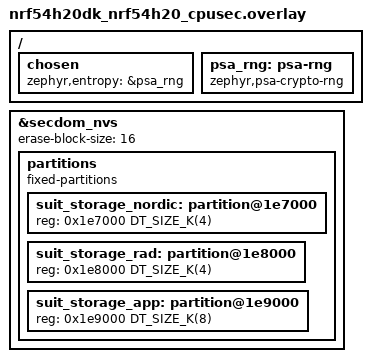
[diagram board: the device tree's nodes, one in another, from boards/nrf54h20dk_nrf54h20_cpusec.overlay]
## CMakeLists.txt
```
#
# Copyright (c) 2023 Nordic Semiconductor ASA
#
# SPDX-License-Identifier: LicenseRef-Nordic-5-Clause
#

cmake_minimum_required(VERSION 3.20.0)

find_package(Zephyr REQUIRED HINTS $ENV{ZEPHYR_BASE})

project(integration_test_suit_orchestrator)
include(../cmake/test_template.cmake)

# Link with the CMake target, that includes SUIT platform internal APIs header
zephyr_library_link_libraries(suit)
zephyr_library_link_libraries(suit_orchestrator_interface)
zephyr_library_link_libraries(suit_utils)
zephyr_library_link_libraries(suit_storage_interface)
zephyr_library_link_libraries(suit_update_magic_values)
zephyr_library_link_libraries(suit_cache_interface)
zephyr_library_link_libraries(suit_execution_mode)
```

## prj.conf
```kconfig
#
# Copyright (c) 2023 Nordic Semiconductor ASA
#
# SPDX-License-Identifier: LicenseRef-Nordic-5-Clause
#

CONFIG_ZTEST=y
CONFIG_ZTEST_NEW_API=y

CONFIG_SUIT=y
CONFIG_SUIT_CRYPTO=y
CONFIG_SUIT_MCI=y
CONFIG_SUIT_MCI_IMPL_CUSTOM=y
CONFIG_SUIT_METADATA=y
CONFIG_SUIT_ORCHESTRATOR=y
CONFIG_SUIT_PROCESSOR=y
CONFIG_SUIT_PLATFORM=y
CONFIG_SUIT_LOG_LEVEL_DBG=y

CONFIG_SUIT_UTILS=y
CONFIG_SUIT_CACHE=y
CONFIG_SUIT_STORAGE=y
CONFIG_SUIT_MEMPTR_STORAGE=y
CONFIG_SUIT_EXECUTION_MODE=y

CONFIG_ZCBOR=y
CONFIG_ZCBOR_CANONICAL=y

CONFIG_FLASH=y

CONFIG_SUIT_DEVCONFIG=y
CONFIG_SUIT_PLAT_CHECK_COMPONENT_COMPATIBILITY=y
CONFIG_SUIT_PLAT_CHECK_CLASSES=y
CONFIG_SUIT_AUTHENTICATE=y

CONFIG_SUIT_DIGEST=y
CONFIG_SUIT_DIGEST_CACHE=y
CONFIG_SUIT_SINK_SELECTOR=y

CONFIG_SUIT_STREAM=y
CONFIG_SUIT_STREAM_SINK_DIGEST=y
CONFIG_SUIT_CHECK_IMAGE_MATCH=y

CONFIG_SUIT_STREAM_SINK_MEMPTR=y
CONFIG_SUIT_STREAM_SINK_FLASH=y
CONFIG_FLASH_MAP=y
CONFIG_SUIT_STREAM_SOURCE_MEMPTR=y
CONFIG_SUIT_STREAM_SOURCE_CACHE=y
```

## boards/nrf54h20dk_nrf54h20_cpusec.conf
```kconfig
#
# Copyright (c) 2023 Nordic Semiconductor ASA
#
# SPDX-License-Identifier: LicenseRef-Nordic-5-Clause
#

CONFIG_NULL_POINTER_EXCEPTION_DETECTION_NONE=y
CONFIG_SERIAL=y
CONFIG_CONSOLE=y
CONFIG_UART_CONSOLE=y

# This test does not set 'IS_SECURE_DOMAIN_FW'. Hence, we need to enable the
# bare minimum configurations for running on bare metal Secure Domain.
CONFIG_SECDOM_UNIT_TEST_SUPPORT=y

# Logging and printk is using standard UART.
CONFIG_LOG_MODE_DEFERRED=y
CONFIG_LOG_BACKEND_UART=y
CONFIG_LOG_PRINTK=y
CONFIG_LOG_BUFFER_SIZE=8192
CONFIG_SOC_FLASH_NRF_MRAM_ONE_BYTE_WRITE_ACCESS=y

# Configure MPI, so it matches the test-specific MCI
CONFIG_SUIT_MPI_GENERATE=y
CONFIG_SUIT_MPI_ROOT_CLASS_NAME="test_sample_root"
CONFIG_SUIT_MPI_ROOT_INDEPENDENT_UPDATE=y
CONFIG_SUIT_MPI_ROOT_SIGNATURE_CHECK_ENABLED_ON_UPDATE_AND_BOOT=y
CONFIG_SUIT_MPI_APP_LOCAL_1=y
CONFIG_SUIT_MPI_APP_LOCAL_1_CLASS_NAME="test_sample_app"
CONFIG_SUIT_MPI_APP_LOCAL_1_INDEPENDENT_UPDATE=n
CONFIG_SUIT_MPI_APP_LOCAL_1_SIGNATURE_CHECK_ENABLED_ON_UPDATE_AND_BOOT=y
```

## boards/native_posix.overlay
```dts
/*
 * Copyright (c) 2023 Nordic Semiconductor ASA
 *
 * SPDX-License-Identifier: LicenseRef-Nordic-5-Clause
 */

&flash0 {
	partitions {
		compatible = "fixed-partitions";
		#address-cells = <1>;
		#size-cells = <1>;

		/* Use the last 32KB of NVM as suit storage. */
		suit_storage: partition@f8000 {
			label = "suit_storage";
			reg = <0xf8000 DT_SIZE_K(32)>;
		};
	};
};
```

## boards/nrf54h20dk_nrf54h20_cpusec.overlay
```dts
/*
 * Copyright (c) 2023 Nordic Semiconductor ASA
 *
 * SPDX-License-Identifier: LicenseRef-Nordic-5-Clause
 */

/ {
	chosen {
		zephyr,entropy = &psa_rng;
	};

	psa_rng: psa-rng {
		compatible = "zephyr,psa-crypto-rng";
		status = "okay";
	};
};

&secdom_nvs {
	erase-block-size = <16>;

	partitions {
		compatible = "fixed-partitions";
		#address-cells = <1>;
		#size-cells = <1>;

		/* Use the last 32 kB of SecDom SUIT NVM storage. */
		/* Use the first 4kB as area reserved for Secure domain. */
		suit_storage_nordic: partition@1e7000 {
			reg = <0x1e7000 DT_SIZE_K(4)>;
		};

		/* Use the next 4kB as area reserved for Radio domain. */
		suit_storage_rad: partition@1e8000 {
			reg = <0x1e8000 DT_SIZE_K(4)>;
		};

		/* Use the next 8kB as area reserved for Application domain. */
		suit_storage_app: partition@1e9000 {
			reg = <0x1e9000 DT_SIZE_K(8)>;
		};
	};
};
```

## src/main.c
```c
/*
 * Copyright (c) 2023 Nordic Semiconductor ASA
 *
 * SPDX-License-Identifier: LicenseRef-Nordic-5-Clause
 */

#include <zephyr/ztest.h>

#include <suit_orchestrator.h>

#include <suit_storage.h>
#include <suit_mci.h>
#include <suit_types.h>
#include <zephyr/drivers/flash.h>
#include <zephyr/storage/flash_map.h>
#include <suit_plat_mem_util.h>
#include <update_magic_values.h>
#include <dfu_cache.h>

#if DT_NODE_EXISTS(DT_NODELABEL(suit_storage_app))
#define SUIT_STORAGE_OFFSET FIXED_PARTITION_OFFSET(suit_storage_app)
#define SUIT_STORAGE_SIZE   FIXED_PARTITION_SIZE(suit_storage_app)
#else
#define SUIT_STORAGE_OFFSET FIXED_PARTITION_OFFSET(suit_storage)
#define SUIT_STORAGE_SIZE   FIXED_PARTITION_SIZE(suit_storage)
#endif
#define SUIT_STORAGE_ADDRESS suit_plat_mem_nvm_ptr_get(SUIT_STORAGE_OFFSET)

const suit_manifest_class_id_t supported_class_id = {{0x5b, 0x46, 0x9f, 0xd1, 0x90, 0xee, 0x53,
						      0x9c, 0xa3, 0x18, 0x68, 0x1b, 0x03, 0x69,
						      0x5e, 0x36}};

/* Valid envelope */
extern const uint8_t manifest_valid_buf[];
extern const size_t manifest_valid_len;

/* Manifest generated using component id with size field set to zero */
extern const uint8_t manifest_zero_size_buf[];
extern const size_t manifest_zero_size_len;

/* Originally valid envelope with manipulated single byte */
extern const uint8_t manifest_manipulated_buf[];
extern const size_t manifest_manipulated_len;

/* Envelope generated with "UNSUPPORTED!" as a component type */
extern const uint8_t manifest_unsupported_component_buf[];
extern const size_t manifest_unsupported_component_len;

/* Envelope with manifest version set to 2 */
extern const uint8_t manifest_wrong_version_buf[];
extern const size_t manifest_wrong_version_len;

/* Envelope signed with a different private key */
extern const uint8_t manifest_different_key_buf[];
extern const size_t manifest_different_key_len;

static void setup_erased_flash(void)
{
	/* Execute SUIT storage init, so the MPI area is copied into a backup region. */
	int err = suit_storage_init();
	zassert_equal(SUIT_PLAT_SUCCESS, err, "Failed to init and backup suit storage (%d)", err);

	/* Clear the whole application area */
	const struct device *fdev = DEVICE_DT_GET(DT_CHOSEN(zephyr_flash_controller));
	zassert_not_null(fdev, "Unable to find a driver to erase storage area");

	err = flash_erase(fdev, SUIT_STORAGE_OFFSET, SUIT_STORAGE_SIZE);
	zassert_equal(0, err, "Unable to erase storage before test execution");
}

static void setup_update_candidate(const uint8_t *buf, size_t len)
{
	zassert_not_null(buf, "NULL buf");

	suit_plat_mreg_t update_candidate[1] = {{
		.mem = buf,
		.size = len,
	}};

	setup_erased_flash();

	int err = suit_storage_init();
	zassert_equal(SUIT_PLAT_SUCCESS, err, "Failed to init suit storage (%d)", err);

	err = suit_storage_update_cand_set(update_candidate, ARRAY_SIZE(update_candidate));
	zassert_equal(SUIT_PLAT_SUCCESS, err,
		      "Unable to set update candidate before test execution (0x%x, %d)", buf, len);
}

ZTEST_SUITE(orchestrator_tests, NULL, NULL, NULL, NULL, NULL);

ZTEST(orchestrator_tests, test_boot_path_empty_storage)
{
	/* GIVEN empty flash (suit storage is erased)... */
	setup_erased_flash();
	/* ... and suit orchestrator is initialized */
	zassert_equal(0, suit_orchestrator_init(), "Orchestrator not initialized");

	/* WHEN orchestrator is launched */
	int err = suit_orchestrator_entry();

	/* THEN emergency recovery is triggered... */
	/* ... and orchestrator exits without an error */
	zassert_equal(0, err, "Unexpected error code");
}

ZTEST(orchestrator_tests, test_update_path_successful_update)
{
	uint8_t *addr;
	size_t size;

	/* GIVEN valid update candidate in suit storage... */
	setup_update_candidate(manifest_valid_buf, manifest_valid_len);
	/* ... and suit orchestrator is initialized */
	zassert_equal(0, suit_orchestrator_init(), "Orchestrator not initialized");

	/* WHEN orchestrator is launched */
	int err = suit_orchestrator_entry();

	/* THEN installation is performed successfully... */
	/* ... and orchestrator exits without an error */
	zassert_equal(0, err, "Unexpected error code");
	/* ... and the envelope get installed */
	err = suit_storage_installed_envelope_get(&supported_class_id, &addr, &size);
	zassert_equal(SUIT_PLAT_SUCCESS, err,
		      "The envelope was not installed after successful update");
}

ZTEST(orchestrator_tests, test_boot_path_successful_boot)
{
	uint8_t *addr_boot;
	size_t size_boot;
	uint8_t *addr_update;
	size_t size_update;

	/* GIVEN valid update candidate in suit storage... */
	setup_update_candidate(manifest_valid_buf, manifest_valid_len);
	/* ... and suit orchestrator is initialized... */
	zassert_equal(0, suit_orchestrator_init(), "Orchestrator not initialized first time");
	/* ... and orchestrator is launched first time to perform successful update */
	zassert_equal(0, suit_orchestrator_entry(), "Unsuccessful first orchestrator launch");
	/* ... and the bootable envelope is installed */
	int err = suit_storage_installed_envelope_get(&supported_class_id, &addr_boot, &size_boot);
	zassert_equal(SUIT_PLAT_SUCCESS, err,
		      "The envelope was not installed after successful update");

	/* WHEN when orchestrator is initialized again (reboot simulation)... */
	zassert_equal(0, suit_orchestrator_init(), "Orchestrator not initialized second time");
	/* ... and orchestrator is launched again */
	err = suit_orchestrator_entry();

	/* THEN installed SW is invoked successfully (orchestrator returns no error) */
	zassert_equal(0, err, "Unexpected error code");
	/* ... and the envelope remains installed */
	err = suit_storage_installed_envelope_get(&supported_class_id, &addr_update, &size_update);
	zassert_equal(SUIT_PLAT_SUCCESS, err,
		      "The envelope was not installed after successful update");
	/* .. and the same index in SUIT storage is used */
	zassert_equal(addr_boot, addr_update,
		      "The envelope was not installed in the same SUIT storage slot");
}

ZTEST(orchestrator_tests, test_update_path_size_zero)
{
	const suit_plat_mreg_t *regions = NULL;
	size_t len = 0;

	/* GIVEN suit storage contains envelope with component id's size field set to zero... */
	setup_update_candidate(manifest_zero_size_buf, manifest_zero_size_len);
	/* ... and orchestrator is initialized */
	zassert_equal(0, suit_orchestrator_init(), "Failed to setup test");

	/* WHEN orchestrator is launched */
	int err = suit_orchestrator_entry();

	/* THEN candidate availability flag is cleared... */
	suit_plat_err_t ret = suit_storage_update_cand_get(&regions, &len);
	zassert_equal(SUIT_PLAT_ERR_NOT_FOUND, ret, "Update candidate presence not cleared");

	/* ... and orchestrator returns success */
	zassert_equal(0, err, "Unexpected error code");
}

ZTEST(orchestrator_tests, test_update_path_manipulated_envelope)
{
	const suit_plat_mreg_t *regions = NULL;
	size_t len = 0;

	/* GIVEN suit storage contains envelope with one of its byte changed to different value...
	 */
	setup_update_candidate(manifest_manipulated_buf, manifest_manipulated_len);
	/* ... and suit orchestrator is initialized */
	zassert_equal(0, suit_orchestrator_init(), "Orchestrator not initialized");

	/* WHEN orchestrator is launched */
	int err = suit_orchestrator_entry();

	/* THEN candidate availability flag is cleared... */
	suit_plat_err_t ret = suit_storage_update_cand_get(&regions, &len);
	zassert_equal(SUIT_PLAT_ERR_NOT_FOUND, ret, "Update candidate presence not cleared");

	/* ... and orchestrator returns success */
	zassert_equal(0, err, "Unexpected error code");
}

ZTEST(orchestrator_tests, test_update_path_candidate_invalid_address_and_size)
{
	const suit_plat_mreg_t *regions = NULL;

	/* GIVEN suit storage indicates presence of update candidate... */
	/* ... but has empty address field...*/
	const uint8_t *buf = (const uint8_t *)UPDATE_MAGIC_VALUE_EMPTY;
	/* ... and has empty size field... */
	size_t len = (size_t)UPDATE_MAGIC_VALUE_EMPTY;
	setup_update_candidate(buf, len);

	/* ... and orchestrator is initialized */
	zassert_equal(0, suit_orchestrator_init(), "Orchestrator not initialized");

	/* WHEN orchestrator is launched */
	int err = suit_orchestrator_entry();

	/* THEN candidate availability flag is cleared... */
	suit_plat_err_t ret = suit_storage_update_cand_get(&regions, &len);
	zassert_equal(SUIT_PLAT_ERR_NOT_FOUND, ret, "Update candidate presence not cleared");

	/* ... and orchestrator returns success */
	zassert_equal(0, err, "Unexpected error code");
}

ZTEST(orchestrator_tests, test_update_path_candidate_empty_size)
{
	const suit_plat_mreg_t *regions = NULL;

	/* GIVEN suit storage has update candidate flag set... */
	/* ...and some non-empty and non-zero address field...*/
	const uint8_t *buf = (const uint8_t *)0xDEADBEEF;
	/* ... but empty size field... */
	size_t len = (size_t)UPDATE_MAGIC_VALUE_EMPTY;
	setup_update_candidate(buf, len);

	/* ... and orchestrator is initialized */
	zassert_equal(0, suit_orchestrator_init(), "Orchestrator not initialized");

	/* WHEN orchestrator is launched */
	int err = suit_orchestrator_entry();

	/* THEN candidate availability flag is cleared... */
	suit_plat_err_t ret = suit_storage_update_cand_get(&regions, &len);
	zassert_equal(SUIT_PLAT_ERR_NOT_FOUND, ret, "Update candidate presence not cleared");

	/* ... and orchestrator returns success */
	zassert_equal(0, err, "Unexpected error code");
}

ZTEST(orchestrator_tests, test_update_path_unsupported_component)
{
	const suit_plat_mreg_t *regions = NULL;
	size_t len = 0;

	/* GIVEN suit storage contains update candidate with unsupported component... */
	setup_update_candidate(manifest_unsupported_component_buf,
			       manifest_unsupported_component_len);
	/* ... and orchestrator is initialized */
	zassert_equal(0, suit_orchestrator_init(), "Orchestrator not initialized");

	/* WHEN orchestrator is launched */
	int err = suit_orchestrator_entry();

	/* THEN candidate availability flag is cleared... */
	suit_plat_err_t ret = suit_storage_update_cand_get(&regions, &len);
	zassert_equal(SUIT_PLAT_ERR_NOT_FOUND, ret, "Update candidate presence not cleared");

	/* ... and orchestrator returns success */
	zassert_equal(0, err, "Unexpected error code");
}

ZTEST(orchestrator_tests, test_update_path_wrong_manifest_version)
{
	const suit_plat_mreg_t *regions = NULL;
	size_t len = 0;

	/* GIVEN suit storage contains update candidate with invalid manifest version... */
	setup_update_candidate(manifest_wrong_version_buf, manifest_wrong_version_len);

	/* ... and orchestrator is initialized */
	zassert_equal(0, suit_orchestrator_init(), "Orchestrator not initialized");

	/* WHEN orchestrator is launched */
	int err = suit_orchestrator_entry();

	/* THEN candidate availability flag is cleared... */
	suit_plat_err_t ret = suit_storage_update_cand_get(&regions, &len);
	zassert_equal(SUIT_PLAT_ERR_NOT_FOUND, ret, "Update candidate presence not cleared");

	/* ... and orchestrator returns success */
	zassert_equal(0, err, "Unexpected error code");
}

ZTEST(orchestrator_tests, test_update_path_signed_with_different_key)
{
	const suit_plat_mreg_t *regions = NULL;
	size_t len = 0;

	/* GIVEN suit storage contains update candidate with invalid manifest version... */
	setup_update_candidate(manifest_different_key_buf, manifest_different_key_len);

	/* ... and orchestrator is initialized */
	zassert_equal(0, suit_orchestrator_init(), "Orchestrator not initialized");

	/* WHEN orchestrator is launched */
	int err = suit_orchestrator_entry();

	/* THEN candidate availability flag is cleared... */
	suit_plat_err_t ret = suit_storage_update_cand_get(&regions, &len);
	zassert_equal(SUIT_PLAT_ERR_NOT_FOUND, ret, "Update candidate presence not cleared");

	/* ... and orchestrator returns success */
	zassert_equal(0, err, "Unexpected error code");
}
```

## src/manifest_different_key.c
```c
/*
 * Copyright (c) 2023 Nordic Semiconductor ASA
 *
 * SPDX-License-Identifier: LicenseRef-Nordic-5-Clause
 */

#if defined(CONFIG_SOC_NRF52840) || defined(CONFIG_BOARD_NATIVE_POSIX)
#include <stdint.h>
#include <stddef.h>

/** @brief Valid SUIT envelope but signed using different private key
 *
 * @details New, temporary private key was created and used for signing.
 *          Signature won't pass verification with a private key used in our tests.
 */
const uint8_t manifest_different_key_buf[] = {
	0xD8, 0x6B, 0xA4, 0x02, 0x58, 0x7A, 0x82, 0x58, 0x24, 0x82, 0x2F, 0x58, 0x20, 0xA9, 0xF6,
	0x31, 0xAA, 0x0A, 0x36, 0x9D, 0x8A, 0xE8, 0xF2, 0x8F, 0xF2, 0x83, 0x4C, 0x2E, 0x54, 0x65,
	0x37, 0x57, 0xD3, 0x90, 0xDE, 0x10, 0xA4, 0x7C, 0x70, 0xE8, 0x5D, 0x9C, 0xF2, 0xDC, 0x9F,
	0x58, 0x51, 0xD2, 0x84, 0x4A, 0xA2, 0x01, 0x26, 0x04, 0x45, 0x1A, 0x7F, 0xFF, 0xFF, 0xE0,
	0xA0, 0xF6, 0x58, 0x40, 0x22, 0xFD, 0x9A, 0x52, 0x84, 0xE2, 0x15, 0x10, 0x0B, 0xE5, 0x1A,
	0x68, 0x41, 0x1E, 0x7E, 0x18, 0x03, 0x76, 0x58, 0x19, 0xD0, 0xD5, 0x9C, 0xC2, 0xEA, 0x98,
	0x86, 0x63, 0x51, 0x12, 0x82, 0x10, 0x66, 0xC9, 0xFE, 0x28, 0xE1, 0x12, 0xE0, 0xB2, 0x56,
	0xB7, 0xDA, 0xB0, 0x8E, 0xB9, 0x34, 0xCE, 0xA9, 0x5D, 0x27, 0x26, 0xCD, 0xEA, 0x4D, 0x04,
	0x5F, 0x61, 0xF0, 0xC1, 0xD1, 0x9C, 0xBA, 0x2B, 0x03, 0x58, 0xD9, 0xA8, 0x01, 0x01, 0x02,
	0x01, 0x03, 0x58, 0x6E, 0xA2, 0x02, 0x81, 0x84, 0x44, 0x63, 0x4D, 0x45, 0x4D, 0x41, 0x00,
	0x45, 0x1A, 0x00, 0x08, 0x00, 0x00, 0x43, 0x19, 0x10, 0x00, 0x04, 0x58, 0x56, 0x86, 0x14,
	0xA4, 0x01, 0x50, 0x76, 0x17, 0xDA, 0xA5, 0x71, 0xFD, 0x5A, 0x85, 0x8F, 0x94, 0xE2, 0x8D,
	0x73, 0x5C, 0xE9, 0xF4, 0x02, 0x50, 0x5B, 0x46, 0x9F, 0xD1, 0x90, 0xEE, 0x53, 0x9C, 0xA3,
	0x18, 0x68, 0x1B, 0x03, 0x69, 0x5E, 0x36, 0x03, 0x58, 0x24, 0x82, 0x2F, 0x58, 0x20, 0x5F,
	0xC3, 0x54, 0xBF, 0x8E, 0x8C, 0x50, 0xFB, 0x4F, 0xBC, 0x2C, 0xFA, 0xEB, 0x04, 0x53, 0x41,
	0xC9, 0x80, 0x6D, 0xEA, 0xBD, 0xCB, 0x41, 0x54, 0xFB, 0x79, 0xCC, 0xA4, 0xF0, 0xC9, 0x8C,
	0x12, 0x0E, 0x19, 0x01, 0x00, 0x01, 0x0F, 0x02, 0x0F, 0x07, 0x43, 0x82, 0x03, 0x0F, 0x09,
	0x43, 0x82, 0x17, 0x02, 0x11, 0x52, 0x86, 0x14, 0xA1, 0x15, 0x69, 0x23, 0x66, 0x69, 0x6C,
	0x65, 0x2E, 0x62, 0x69, 0x6E, 0x15, 0x02, 0x03, 0x0F, 0x17, 0x82, 0x2F, 0x58, 0x20, 0x8C,
	0x70, 0x17, 0x9B, 0x73, 0x6B, 0x68, 0x9F, 0x02, 0x7D, 0x2D, 0xF6, 0x78, 0x00, 0xB0, 0xA4,
	0x38, 0x52, 0x8F, 0x9C, 0x67, 0xA1, 0x37, 0xF4, 0xB0, 0xCA, 0x78, 0xCB, 0x36, 0x96, 0x16,
	0x4F, 0x05, 0x82, 0x4C, 0x6B, 0x49, 0x4E, 0x53, 0x54, 0x4C, 0x44, 0x5F, 0x4D, 0x46, 0x53,
	0x54, 0x50, 0x5B, 0x46, 0x9F, 0xD1, 0x90, 0xEE, 0x53, 0x9C, 0xA3, 0x18, 0x68, 0x1B, 0x03,
	0x69, 0x5E, 0x36, 0x17, 0x58, 0x82, 0xA1, 0x84, 0x44, 0x63, 0x4D, 0x45, 0x4D, 0x41, 0x00,
	0x45, 0x1A, 0x00, 0x08, 0x00, 0x00, 0x43, 0x19, 0x10, 0x00, 0xA6, 0x01, 0x78, 0x18, 0x4E,
	0x6F, 0x72, 0x64, 0x69, 0x63, 0x20, 0x53, 0x65, 0x6D, 0x69, 0x63, 0x6F, 0x6E, 0x64, 0x75,
	0x63, 0x74, 0x6F, 0x72, 0x20, 0x41, 0x53, 0x41, 0x02, 0x64, 0x74, 0x65, 0x73, 0x74, 0x03,
	0x6E, 0x6E, 0x6F, 0x72, 0x64, 0x69, 0x63, 0x73, 0x65, 0x6D, 0x69, 0x2E, 0x63, 0x6F, 0x6D,
	0x04, 0x74, 0x54, 0x68, 0x65, 0x20, 0x74, 0x65, 0x73, 0x74, 0x20, 0x61, 0x70, 0x70, 0x6C,
	0x69, 0x63, 0x61, 0x74, 0x69, 0x6F, 0x6E, 0x05, 0x78, 0x1C, 0x53, 0x61, 0x6D, 0x70, 0x6C,
	0x65, 0x20, 0x61, 0x70, 0x70, 0x6C, 0x69, 0x63, 0x61, 0x74, 0x69, 0x6F, 0x6E, 0x20, 0x66,
	0x6F, 0x72, 0x20, 0x74, 0x65, 0x73, 0x74, 0x73, 0x06, 0x66, 0x76, 0x31, 0x2E, 0x30, 0x2E,
	0x30, 0x69, 0x23, 0x66, 0x69, 0x6C, 0x65, 0x2E, 0x62, 0x69, 0x6E, 0x59, 0x01, 0x00, 0xC7,
	0x9C, 0xAB, 0x9D, 0xE8, 0x33, 0x7F, 0x30, 0x14, 0xEB, 0xAC, 0x02, 0xAF, 0x26, 0x01, 0x5E,
	0x80, 0x6D, 0x88, 0xA1, 0xDB, 0x11, 0xA7, 0x31, 0xDF, 0xA6, 0xEC, 0xCB, 0x9B, 0x48, 0x0D,
	0xC8, 0x34, 0x40, 0x6D, 0x30, 0x86, 0x7D, 0xE8, 0x1B, 0xEC, 0x3C, 0xF5, 0x40, 0xD0, 0x48,
	0x18, 0x82, 0x11, 0x9D, 0x7C, 0x3F, 0x6C, 0xE5, 0x8F, 0xF1, 0xD3, 0x5D, 0xE1, 0x51, 0xF7,
	0x6A, 0x0F, 0xAF, 0x0B, 0xBD, 0x4C, 0x5F, 0xA5, 0x34, 0x1A, 0x66, 0xDB, 0x22, 0xEC, 0x63,
	0xED, 0x4B, 0xAB, 0xC7, 0xC8, 0xF7, 0x59, 0xD8, 0xD6, 0x9E, 0xEC, 0x71, 0x1B, 0x24, 0x20,
	0xB9, 0xAE, 0xE1, 0x3B, 0xFC, 0xAE, 0xB8, 0x77, 0xAC, 0xA4, 0x57, 0x34, 0x97, 0x84, 0x4F,
	0x58, 0xD5, 0x68, 0x08, 0x6F, 0xE3, 0x9C, 0x7E, 0x1B, 0xD7, 0x38, 0x22, 0x98, 0x48, 0xF8,
	0x7A, 0x67, 0xB2, 0xD9, 0xAC, 0xC5, 0x34, 0xC1, 0x27, 0x82, 0x8E, 0x42, 0x79, 0x84, 0x21,
	0x37, 0x4C, 0x41, 0x4A, 0x0F, 0xE2, 0x7F, 0xA0, 0x6A, 0x19, 0x13, 0x3D, 0x52, 0x22, 0x7F,
	0xD6, 0x2F, 0x71, 0x12, 0x76, 0xAB, 0x25, 0x9C, 0xFC, 0x67, 0x08, 0x03, 0x7C, 0xDB, 0x18,
	0xE6, 0x45, 0xF8, 0x99, 0xC2, 0x9E, 0x2C, 0xE3, 0x9B, 0x25, 0xA9, 0x7B, 0x09, 0xFF, 0x00,
	0x57, 0x26, 0x08, 0x0A, 0x11, 0x42, 0xCF, 0x82, 0xA2, 0x6B, 0x2A, 0x99, 0xF9, 0x71, 0x9D,
	0x14, 0x19, 0x5C, 0x5C, 0x78, 0x31, 0x60, 0x42, 0x4A, 0x18, 0x1F, 0xEC, 0x78, 0x6A, 0x9A,
	0x7C, 0x4F, 0xCF, 0xE8, 0x5A, 0x29, 0x65, 0xCD, 0x01, 0x3B, 0x6D, 0x53, 0xBB, 0xC6, 0xDB,
	0xDA, 0xD5, 0x8F, 0xF7, 0xF4, 0xD9, 0xB9, 0x0A, 0x03, 0x4B, 0xFF, 0x33, 0xAB, 0x3B, 0xC5,
	0xAF, 0xD0, 0xB8, 0x2C, 0x0F, 0x6A, 0xA9, 0x11, 0xB0, 0xE8, 0x57, 0x8C, 0x92, 0x53, 0x81};

const size_t manifest_different_key_len = sizeof(manifest_different_key_buf);

#endif /* CONFIG_SOC_NRF52840 || CONFIG_BOARD_NATIVE_POSIX */
```

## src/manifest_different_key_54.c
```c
/*
 * Copyright (c) 2023 Nordic Semiconductor ASA
 *
 * SPDX-License-Identifier: LicenseRef-Nordic-5-Clause
 */

#if defined(CONFIG_SOC_NRF54H20)
#include <stdint.h>
#include <stddef.h>

/** @brief Valid SUIT envelope but signed using different private key
 *
 * @details New, temporary private key was created and used for signing.
 *          Signature won't pass verification with a private key used in our tests.
 */
const uint8_t manifest_different_key_buf[] = {
	0xD8, 0x6B, 0xA4, 0x02, 0x58, 0x7A, 0x82, 0x58, 0x24, 0x82, 0x2F, 0x58, 0x20, 0x67, 0xBE,
	0x1B, 0x3A, 0x2B, 0x20, 0xCC, 0x03, 0x4F, 0xB5, 0xAA, 0x49, 0x82, 0xDF, 0x34, 0x2F, 0x4F,
	0xDD, 0x80, 0x60, 0x71, 0x17, 0x13, 0x87, 0xED, 0x06, 0xA0, 0x4F, 0xD3, 0x31, 0xC3, 0x61,
	0x58, 0x51, 0xD2, 0x84, 0x4A, 0xA2, 0x01, 0x26, 0x04, 0x45, 0x1A, 0x7F, 0xFF, 0xFF, 0xE0,
	0xA0, 0xF6, 0x58, 0x40, 0x67, 0x03, 0xC6, 0x26, 0x2B, 0xB7, 0x29, 0x56, 0xFA, 0x31, 0xF8,
	0x28, 0x14, 0xAB, 0xCB, 0x11, 0x61, 0x9B, 0xF6, 0xC4, 0x54, 0xE6, 0x29, 0xF4, 0x4B, 0xB6,
	0xCD, 0xEE, 0xE2, 0x92, 0xE7, 0xBC, 0x35, 0xE2, 0x23, 0x1A, 0x5F, 0x25, 0x46, 0xD0, 0x21,
	0x4B, 0xFC, 0xB0, 0xA9, 0xE3, 0xBC, 0xD5, 0xA1, 0x1C, 0x18, 0x72, 0xC2, 0xA7, 0x1F, 0x79,
	0x1B, 0x6C, 0x00, 0xBF, 0x84, 0x5F, 0x03, 0xAA, 0x03, 0x58, 0xD9, 0xA8, 0x01, 0x01, 0x02,
	0x01, 0x03, 0x58, 0x6E, 0xA2, 0x02, 0x81, 0x84, 0x44, 0x63, 0x4D, 0x45, 0x4D, 0x41, 0x00,
	0x45, 0x1A, 0x0E, 0x0A, 0xA0, 0x00, 0x43, 0x19, 0x10, 0x00, 0x04, 0x58, 0x56, 0x86, 0x14,
	0xA4, 0x01, 0x50, 0x76, 0x17, 0xDA, 0xA5, 0x71, 0xFD, 0x5A, 0x85, 0x8F, 0x94, 0xE2, 0x8D,
	0x73, 0x5C, 0xE9, 0xF4, 0x02, 0x50, 0x5B, 0x46, 0x9F, 0xD1, 0x90, 0xEE, 0x53, 0x9C, 0xA3,
	0x18, 0x68, 0x1B, 0x03, 0x69, 0x5E, 0x36, 0x03, 0x58, 0x24, 0x82, 0x2F, 0x58, 0x20, 0x5F,
	0xC3, 0x54, 0xBF, 0x8E, 0x8C, 0x50, 0xFB, 0x4F, 0xBC, 0x2C, 0xFA, 0xEB, 0x04, 0x53, 0x41,
	0xC9, 0x80, 0x6D, 0xEA, 0xBD, 0xCB, 0x41, 0x54, 0xFB, 0x79, 0xCC, 0xA4, 0xF0, 0xC9, 0x8C,
	0x12, 0x0E, 0x19, 0x01, 0x00, 0x01, 0x0F, 0x02, 0x0F, 0x07, 0x43, 0x82, 0x03, 0x0F, 0x09,
	0x43, 0x82, 0x17, 0x02, 0x11, 0x52, 0x86, 0x14, 0xA1, 0x15, 0x69, 0x23, 0x66, 0x69, 0x6C,
	0x65, 0x2E, 0x62, 0x69, 0x6E, 0x15, 0x02, 0x03, 0x0F, 0x17, 0x82, 0x2F, 0x58, 0x20, 0x69,
	0x74, 0xD1, 0x61, 0x69, 0x08, 0x2F, 0x10, 0xAE, 0x48, 0x6C, 0x5B, 0x12, 0x82, 0x40, 0x9C,
	0xFD, 0x63, 0xCC, 0xC8, 0x35, 0x4D, 0xBE, 0x55, 0x15, 0xCC, 0xE6, 0xCE, 0x8F, 0x37, 0xDE,
	0x71, 0x05, 0x82, 0x4C, 0x6B, 0x49, 0x4E, 0x53, 0x54, 0x4C, 0x44, 0x5F, 0x4D, 0x46, 0x53,
	0x54, 0x50, 0x5B, 0x46, 0x9F, 0xD1, 0x90, 0xEE, 0x53, 0x9C, 0xA3, 0x18, 0x68, 0x1B, 0x03,
	0x69, 0x5E, 0x36, 0x17, 0x58, 0x82, 0xA1, 0x84, 0x44, 0x63, 0x4D, 0x45, 0x4D, 0x41, 0x00,
	0x45, 0x1A, 0x0E, 0x0A, 0xA0, 0x00, 0x43, 0x19, 0x10, 0x00, 0xA6, 0x01, 0x78, 0x18, 0x4E,
	0x6F, 0x72, 0x64, 0x69, 0x63, 0x20, 0x53, 0x65, 0x6D, 0x69, 0x63, 0x6F, 0x6E, 0x64, 0x75,
	0x63, 0x74, 0x6F, 0x72, 0x20, 0x41, 0x53, 0x41, 0x02, 0x64, 0x74, 0x65, 0x73, 0x74, 0x03,
	0x6E, 0x6E, 0x6F, 0x72, 0x64, 0x69, 0x63, 0x73, 0x65, 0x6D, 0x69, 0x2E, 0x63, 0x6F, 0x6D,
	0x04, 0x74, 0x54, 0x68, 0x65, 0x20, 0x74, 0x65, 0x73, 0x74, 0x20, 0x61, 0x70, 0x70, 0x6C,
	0x69, 0x63, 0x61, 0x74, 0x69, 0x6F, 0x6E, 0x05, 0x78, 0x1C, 0x53, 0x61, 0x6D, 0x70, 0x6C,
	0x65, 0x20, 0x61, 0x70, 0x70, 0x6C, 0x69, 0x63, 0x61, 0x74, 0x69, 0x6F, 0x6E, 0x20, 0x66,
	0x6F, 0x72, 0x20, 0x74, 0x65, 0x73, 0x74, 0x73, 0x06, 0x66, 0x76, 0x31, 0x2E, 0x30, 0x2E,
	0x30, 0x69, 0x23, 0x66, 0x69, 0x6C, 0x65, 0x2E, 0x62, 0x69, 0x6E, 0x59, 0x01, 0x00, 0xC7,
	0x9C, 0xAB, 0x9D, 0xE8, 0x33, 0x7F, 0x30, 0x14, 0xEB, 0xAC, 0x02, 0xAF, 0x26, 0x01, 0x5E,
	0x80, 0x6D, 0x88, 0xA1, 0xDB, 0x11, 0xA7, 0x31, 0xDF, 0xA6, 0xEC, 0xCB, 0x9B, 0x48, 0x0D,
	0xC8, 0x34, 0x40, 0x6D, 0x30, 0x86, 0x7D, 0xE8, 0x1B, 0xEC, 0x3C, 0xF5, 0x40, 0xD0, 0x48,
	0x18, 0x82, 0x11, 0x9D, 0x7C, 0x3F, 0x6C, 0xE5, 0x8F, 0xF1, 0xD3, 0x5D, 0xE1, 0x51, 0xF7,
	0x6A, 0x0F, 0xAF, 0x0B, 0xBD, 0x4C, 0x5F, 0xA5, 0x34, 0x1A, 0x66, 0xDB, 0x22, 0xEC, 0x63,
	0xED, 0x4B, 0xAB, 0xC7, 0xC8, 0xF7, 0x59, 0xD8, 0xD6, 0x9E, 0xEC, 0x71, 0x1B, 0x24, 0x20,
	0xB9, 0xAE, 0xE1, 0x3B, 0xFC, 0xAE, 0xB8, 0x77, 0xAC, 0xA4, 0x57, 0x34, 0x97, 0x84, 0x4F,
	0x58, 0xD5, 0x68, 0x08, 0x6F, 0xE3, 0x9C, 0x7E, 0x1B, 0xD7, 0x38, 0x22, 0x98, 0x48, 0xF8,
	0x7A, 0x67, 0xB2, 0xD9, 0xAC, 0xC5, 0x34, 0xC1, 0x27, 0x82, 0x8E, 0x42, 0x79, 0x84, 0x21,
	0x37, 0x4C, 0x41, 0x4A, 0x0F, 0xE2, 0x7F, 0xA0, 0x6A, 0x19, 0x13, 0x3D, 0x52, 0x22, 0x7F,
	0xD6, 0x2F, 0x71, 0x12, 0x76, 0xAB, 0x25, 0x9C, 0xFC, 0x67, 0x08, 0x03, 0x7C, 0xDB, 0x18,
	0xE6, 0x45, 0xF8, 0x99, 0xC2, 0x9E, 0x2C, 0xE3, 0x9B, 0x25, 0xA9, 0x7B, 0x09, 0xFF, 0x00,
	0x57, 0x26, 0x08, 0x0A, 0x11, 0x42, 0xCF, 0x82, 0xA2, 0x6B, 0x2A, 0x99, 0xF9, 0x71, 0x9D,
	0x14, 0x19, 0x5C, 0x5C, 0x78, 0x31, 0x60, 0x42, 0x4A, 0x18, 0x1F, 0xEC, 0x78, 0x6A, 0x9A,
	0x7C, 0x4F, 0xCF, 0xE8, 0x5A, 0x29, 0x65, 0xCD, 0x01, 0x3B, 0x6D, 0x53, 0xBB, 0xC6, 0xDB,
	0xDA, 0xD5, 0x8F, 0xF7, 0xF4, 0xD9, 0xB9, 0x0A, 0x03, 0x4B, 0xFF, 0x33, 0xAB, 0x3B, 0xC5,
	0xAF, 0xD0, 0xB8, 0x2C, 0x0F, 0x6A, 0xA9, 0x11, 0xB0, 0xE8, 0x57, 0x8C, 0x92, 0x53, 0x81};

const size_t manifest_different_key_len = sizeof(manifest_different_key_buf);

#endif /* CONFIG_SOC_NRF54H20 */
```

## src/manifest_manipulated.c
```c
/*
 * Copyright (c) 2023 Nordic Semiconductor ASA
 *
 * SPDX-License-Identifier: LicenseRef-Nordic-5-Clause
 */

#if defined(CONFIG_SOC_NRF52840) || defined(CONFIG_BOARD_NATIVE_POSIX)
#include <stdint.h>
#include <stddef.h>

/** @brief Manipulated SUIT envelope, based on ../manifest/sample_valid.yaml
 *
 * @details The manipulation is done on byte of index 7, from value 0x58 to 0xFF
 *
 */
const uint8_t manifest_manipulated_buf[] = {
	0xD8, 0x6B, 0xA4, 0x02, 0x58, 0x7A, 0x82, 0x58, 0x24, 0x82, 0x2F, 0xFF, 0x20, 0x99, 0x0B,
	0xD3, 0xF5, 0x19, 0xBD, 0x5A, 0x13, 0xA3, 0x46, 0x7D, 0x99, 0x75, 0xA6, 0x46, 0x0D, 0x0B,
	0xD7, 0xA5, 0xFE, 0xA4, 0x15, 0x99, 0x27, 0xBC, 0xB1, 0xD5, 0x9B, 0x31, 0x2D, 0x7D, 0xAE,
	0x58, 0x51, 0xD2, 0x84, 0x4A, 0xA2, 0x01, 0x26, 0x04, 0x45, 0x1A, 0x7F, 0xFF, 0xFF, 0xE0,
	0xA0, 0xF6, 0x58, 0x40, 0xFC, 0x79, 0x84, 0xAB, 0x2C, 0xF2, 0x2D, 0xBC, 0x13, 0xF5, 0x2D,
	0x12, 0x6A, 0xE5, 0xDC, 0xC8, 0x84, 0xB0, 0xFF, 0x09, 0xE1, 0x60, 0x0A, 0xBD, 0x86, 0x9F,
	0xED, 0xA4, 0xEB, 0x52, 0x7D, 0x51, 0xC4, 0x31, 0xAB, 0x21, 0x8A, 0x40, 0x58, 0xDC, 0xF3,
	0x6B, 0x1E, 0x2B, 0x83, 0x87, 0x88, 0x96, 0xBD, 0x0D, 0xAB, 0x85, 0x5D, 0x6D, 0xD3, 0x9A,
	0x8B, 0xE1, 0x05, 0xB0, 0xE5, 0x12, 0x5D, 0x2F, 0x03, 0x59, 0x01, 0x07, 0xA8, 0x01, 0x01,
	0x02, 0x01, 0x03, 0x58, 0x66, 0xA3, 0x02, 0x82, 0x82, 0x4A, 0x69, 0x43, 0x41, 0x4E, 0x44,
	0x5F, 0x4D, 0x46, 0x53, 0x54, 0x41, 0x00, 0x82, 0x4C, 0x6B, 0x49, 0x4E, 0x53, 0x54, 0x4C,
	0x44, 0x5F, 0x4D, 0x46, 0x53, 0x54, 0x50, 0x5B, 0x46, 0x9F, 0xD1, 0x90, 0xEE, 0x53, 0x9C,
	0xA3, 0x18, 0x68, 0x1B, 0x03, 0x69, 0x5E, 0x36, 0x04, 0x58, 0x2D, 0x88, 0x0C, 0x01, 0x14,
	0xA2, 0x01, 0x50, 0x76, 0x17, 0xDA, 0xA5, 0x71, 0xFD, 0x5A, 0x85, 0x8F, 0x94, 0xE2, 0x8D,
	0x73, 0x5C, 0xE9, 0xF4, 0x02, 0x50, 0x5B, 0x46, 0x9F, 0xD1, 0x90, 0xEE, 0x53, 0x9C, 0xA3,
	0x18, 0x68, 0x1B, 0x03, 0x69, 0x5E, 0x36, 0x01, 0x0F, 0x02, 0x0F, 0x01, 0xA2, 0x00, 0xA0,
	0x01, 0xA0, 0x07, 0x47, 0x86, 0x0C, 0x01, 0x07, 0x0F, 0x0B, 0x0F, 0x09, 0x47, 0x86, 0x0C,
	0x01, 0x07, 0x0F, 0x0B, 0x0F, 0x11, 0x58, 0x3F, 0x8C, 0x0C, 0x00, 0x14, 0xA2, 0x15, 0x69,
	0x23, 0x61, 0x70, 0x70, 0x2E, 0x73, 0x75, 0x69, 0x74, 0x03, 0x58, 0x24, 0x82, 0x2F, 0x58,
	0x20, 0xA9, 0xF6, 0x31, 0xAA, 0x0A, 0x36, 0x9D, 0x8A, 0xE8, 0xF2, 0x8F, 0xF2, 0x83, 0x4C,
	0x2E, 0x54, 0x65, 0x37, 0x57, 0xD3, 0x90, 0xDE, 0x10, 0xA4, 0x7C, 0x70, 0xE8, 0x5D, 0x9C,
	0xF2, 0xDC, 0x9F, 0x15, 0x02, 0x03, 0x0F, 0x07, 0x0F, 0x0B, 0x0F, 0x17, 0x82, 0x2F, 0x58,
	0x20, 0x4C, 0x3E, 0x23, 0xA0, 0xD3, 0x56, 0xE9, 0xA6, 0xF7, 0xDA, 0xD8, 0x0C, 0xAB, 0x79,
	0x53, 0x8F, 0x88, 0xCD, 0x18, 0xC7, 0x17, 0x35, 0xDE, 0xCB, 0x4A, 0xF5, 0x3C, 0xC2, 0xE8,
	0xD6, 0x26, 0xC9, 0x05, 0x82, 0x4C, 0x6B, 0x49, 0x4E, 0x53, 0x54, 0x4C, 0x44, 0x5F, 0x4D,
	0x46, 0x53, 0x54, 0x50, 0x97, 0x05, 0x48, 0x23, 0x4C, 0x3D, 0x59, 0xA1, 0x89, 0x86, 0xA5,
	0x46, 0x60, 0xA1, 0x4B, 0x0A, 0x17, 0x58, 0x77, 0xA1, 0x82, 0x4A, 0x69, 0x43, 0x41, 0x4E,
	0x44, 0x5F, 0x4D, 0x46, 0x53, 0x54, 0x41, 0x00, 0xA6, 0x01, 0x78, 0x18, 0x4E, 0x6F, 0x72,
	0x64, 0x69, 0x63, 0x20, 0x53, 0x65, 0x6D, 0x69, 0x63, 0x6F, 0x6E, 0x64, 0x75, 0x63, 0x74,
	0x6F, 0x72, 0x20, 0x41, 0x53, 0x41, 0x02, 0x64, 0x74, 0x65, 0x73, 0x74, 0x03, 0x6E, 0x6E,
	0x6F, 0x72, 0x64, 0x69, 0x63, 0x73, 0x65, 0x6D, 0x69, 0x2E, 0x63, 0x6F, 0x6D, 0x04, 0x76,
	0x54, 0x68, 0x65, 0x20, 0x74, 0x65, 0x73, 0x74, 0x20, 0x72, 0x6F, 0x6F, 0x74, 0x20, 0x6D,
	0x61, 0x6E, 0x69, 0x66, 0x65, 0x73, 0x74, 0x05, 0x74, 0x53, 0x61, 0x6D, 0x70, 0x6C, 0x65,
	0x20, 0x72, 0x6F, 0x6F, 0x74, 0x20, 0x6D, 0x61, 0x6E, 0x69, 0x66, 0x65, 0x73, 0x74, 0x06,
	0x66, 0x76, 0x31, 0x2E, 0x30, 0x2E, 0x30, 0x69, 0x23, 0x61, 0x70, 0x70, 0x2E, 0x73, 0x75,
	0x69, 0x74, 0x59, 0x02, 0xEE, 0xD8, 0x6B, 0xA4, 0x02, 0x58, 0x7A, 0x82, 0xFF, 0x24, 0x82,
	0x2F, 0x58, 0x20, 0xA9, 0xF6, 0x31, 0xAA, 0x0A, 0x36, 0x9D, 0x8A, 0xE8, 0xF2, 0x8F, 0xF2,
	0x83, 0x4C, 0x2E, 0x54, 0x65, 0x37, 0x57, 0xD3, 0x90, 0xDE, 0x10, 0xA4, 0x7C, 0x70, 0xE8,
	0x5D, 0x9C, 0xF2, 0xDC, 0x9F, 0x58, 0x51, 0xD2, 0x84, 0x4A, 0xA2, 0x01, 0x26, 0x04, 0x45,
	0x1A, 0x7F, 0xFF, 0xFF, 0xE0, 0xA0, 0xF6, 0x58, 0x40, 0x2A, 0x3C, 0x80, 0x72, 0x92, 0xD5,
	0x5B, 0x48, 0x00, 0x37, 0x5F, 0x80, 0xFB, 0xCC, 0x1D, 0x6E, 0x3A, 0xBE, 0x0B, 0x7B, 0x98,
	0xC7, 0x7D, 0x58, 0x95, 0xA6, 0x8E, 0x22, 0xF0, 0xB2, 0xDE, 0x53, 0x45, 0x7C, 0x4C, 0x22,
	0xB4, 0x43, 0xB6, 0x59, 0x63, 0x8D, 0xF7, 0x01, 0x22, 0xE7, 0xDA, 0xB5, 0x85, 0x34, 0x85,
	0x52, 0x62, 0x81, 0x6D, 0xED, 0x56, 0xC2, 0xBF, 0xE9, 0x95, 0xBD, 0x33, 0xAC, 0x03, 0x58,
	0xD9, 0xA8, 0x01, 0x01, 0x02, 0x01, 0x03, 0x58, 0x6E, 0xA2, 0x02, 0x81, 0x84, 0x44, 0x63,
	0x4D, 0x45, 0x4D, 0x41, 0x00, 0x45, 0x1A, 0x00, 0x08, 0x00, 0x00, 0x43, 0x19, 0x10, 0x00,
	0x04, 0x58, 0x56, 0x86, 0x14, 0xA4, 0x01, 0x50, 0x76, 0x17, 0xDA, 0xA5, 0x71, 0xFD, 0x5A,
	0x85, 0x8F, 0x94, 0xE2, 0x8D, 0x73, 0x5C, 0xE9, 0xF4, 0x02, 0x50, 0x5B, 0x46, 0x9F, 0xD1,
	0x90, 0xEE, 0x53, 0x9C, 0xA3, 0x18, 0x68, 0x1B, 0x03, 0x69, 0x5E, 0x36, 0x03, 0x58, 0x24,
	0x82, 0x2F, 0x58, 0x20, 0x5F, 0xC3, 0x54, 0xBF, 0x8E, 0x8C, 0x50, 0xFB, 0x4F, 0xBC, 0x2C,
	0xFA, 0xEB, 0x04, 0x53, 0x41, 0xC9, 0x80, 0x6D, 0xEA, 0xBD, 0xCB, 0x41, 0x54, 0xFB, 0x79,
	0xCC, 0xA4, 0xF0, 0xC9, 0x8C, 0x12, 0x0E, 0x19, 0x01, 0x00, 0x01, 0x0F, 0x02, 0x0F, 0x07,
	0x43, 0x82, 0x03, 0x0F, 0x09, 0x43, 0x82, 0x17, 0x02, 0x11, 0x52, 0x86, 0x14, 0xA1, 0x15,
	0x69, 0x23, 0x66, 0x69, 0x6C, 0x65, 0x2E, 0x62, 0x69, 0x6E, 0x15, 0x02, 0x03, 0x0F, 0x17,
	0x82, 0x2F, 0x58, 0x20, 0x8C, 0x70, 0x17, 0x9B, 0x73, 0x6B, 0x68, 0x9F, 0x02, 0x7D, 0x2D,
	0xF6, 0x78, 0x00, 0xB0, 0xA4, 0x38, 0x52, 0x8F, 0x9C, 0x67, 0xA1, 0x37, 0xF4, 0xB0, 0xCA,
	0x78, 0xCB, 0x36, 0x96, 0x16, 0x4F, 0x05, 0x82, 0x4C, 0x6B, 0x49, 0x4E, 0x53, 0x54, 0x4C,
	0x44, 0x5F, 0x4D, 0x46, 0x53, 0x54, 0x50, 0x5B, 0x46, 0x9F, 0xD1, 0x90, 0xEE, 0x53, 0x9C,
	0xA3, 0x18, 0x68, 0x1B, 0x03, 0x69, 0x5E, 0x36, 0x17, 0x58, 0x82, 0xA1, 0x84, 0x44, 0x63,
	0x4D, 0x45, 0x4D, 0x41, 0x00, 0x45, 0x1A, 0x00, 0x08, 0x00, 0x00, 0x43, 0x19, 0x10, 0x00,
	0xA6, 0x01, 0x78, 0x18, 0x4E, 0x6F, 0x72, 0x64, 0x69, 0x63, 0x20, 0x53, 0x65, 0x6D, 0x69,
	0x63, 0x6F, 0x6E, 0x64, 0x75, 0x63, 0x74, 0x6F, 0x72, 0x20, 0x41, 0x53, 0x41, 0x02, 0x64,
	0x74, 0x65, 0x73, 0x74, 0x03, 0x6E, 0x6E, 0x6F, 0x72, 0x64, 0x69, 0x63, 0x73, 0x65, 0x6D,
	0x69, 0x2E, 0x63, 0x6F, 0x6D, 0x04, 0x74, 0x54, 0x68, 0x65, 0x20, 0x74, 0x65, 0x73, 0x74,
	0x20, 0x61, 0x70, 0x70, 0x6C, 0x69, 0x63, 0x61, 0x74, 0x69, 0x6F, 0x6E, 0x05, 0x78, 0x1C,
	0x53, 0x61, 0x6D, 0x70, 0x6C, 0x65, 0x20, 0x61, 0x70, 0x70, 0x6C, 0x69, 0x63, 0x61, 0x74,
	0x69, 0x6F, 0x6E, 0x20, 0x66, 0x6F, 0x72, 0x20, 0x74, 0x65, 0x73, 0x74, 0x73, 0x06, 0x66,
	0x76, 0x31, 0x2E, 0x30, 0x2E, 0x30, 0x69, 0x23, 0x66, 0x69, 0x6C, 0x65, 0x2E, 0x62, 0x69,
	0x6E, 0x59, 0x01, 0x00, 0xC7, 0x9C, 0xAB, 0x9D, 0xE8, 0x33, 0x7F, 0x30, 0x14, 0xEB, 0xAC,
	0x02, 0xAF, 0x26, 0x01, 0x5E, 0x80, 0x6D, 0x88, 0xA1, 0xDB, 0x11, 0xA7, 0x31, 0xDF, 0xA6,
	0xEC, 0xCB, 0x9B, 0x48, 0x0D, 0xC8, 0x34, 0x40, 0x6D, 0x30, 0x86, 0x7D, 0xE8, 0x1B, 0xEC,
	0x3C, 0xF5, 0x40, 0xD0, 0x48, 0x18, 0x82, 0x11, 0x9D, 0x7C, 0x3F, 0x6C, 0xE5, 0x8F, 0xF1,
	0xD3, 0x5D, 0xE1, 0x51, 0xF7, 0x6A, 0x0F, 0xAF, 0x0B, 0xBD, 0x4C, 0x5F, 0xA5, 0x34, 0x1A,
	0x66, 0xDB, 0x22, 0xEC, 0x63, 0xED, 0x4B, 0xAB, 0xC7, 0xC8, 0xF7, 0x59, 0xD8, 0xD6, 0x9E,
	0xEC, 0x71, 0x1B, 0x24, 0x20, 0xB9, 0xAE, 0xE1, 0x3B, 0xFC, 0xAE, 0xB8, 0x77, 0xAC, 0xA4,
	0x57, 0x34, 0x97, 0x84, 0x4F, 0x58, 0xD5, 0x68, 0x08, 0x6F, 0xE3, 0x9C, 0x7E, 0x1B, 0xD7,
	0x38, 0x22, 0x98, 0x48, 0xF8, 0x7A, 0x67, 0xB2, 0xD9, 0xAC, 0xC5, 0x34, 0xC1, 0x27, 0x82,
	0x8E, 0x42, 0x79, 0x84, 0x21, 0x37, 0x4C, 0x41, 0x4A, 0x0F, 0xE2, 0x7F, 0xA0, 0x6A, 0x19,
	0x13, 0x3D, 0x52, 0x22, 0x7F, 0xD6, 0x2F, 0x71, 0x12, 0x76, 0xAB, 0x25, 0x9C, 0xFC, 0x67,
	0x08, 0x03, 0x7C, 0xDB, 0x18, 0xE6, 0x45, 0xF8, 0x99, 0xC2, 0x9E, 0x2C, 0xE3, 0x9B, 0x25,
	0xA9, 0x7B, 0x09, 0xFF, 0x00, 0x57, 0x26, 0x08, 0x0A, 0x11, 0x42, 0xCF, 0x82, 0xA2, 0x6B,
	0x2A, 0x99, 0xF9, 0x71, 0x9D, 0x14, 0x19, 0x5C, 0x5C, 0x78, 0x31, 0x60, 0x42, 0x4A, 0x18,
	0x1F, 0xEC, 0x78, 0x6A, 0x9A, 0x7C, 0x4F, 0xCF, 0xE8, 0x5A, 0x29, 0x65, 0xCD, 0x01, 0x3B,
	0x6D, 0x53, 0xBB, 0xC6, 0xDB, 0xDA, 0xD5, 0x8F, 0xF7, 0xF4, 0xD9, 0xB9, 0x0A, 0x03, 0x4B,
	0xFF, 0x33, 0xAB, 0x3B, 0xC5, 0xAF, 0xD0, 0xB8, 0x2C, 0x0F, 0x6A, 0xA9, 0x11, 0xB0, 0xE8,
	0x57, 0x8C, 0x92, 0x53, 0x81};

const size_t manifest_manipulated_len = sizeof(manifest_manipulated_buf);

#endif /* CONFIG_SOC_NRF52840 || CONFIG_BOARD_NATIVE_POSIX */
```

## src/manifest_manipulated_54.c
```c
/*
 * Copyright (c) 2023 Nordic Semiconductor ASA
 *
 * SPDX-License-Identifier: LicenseRef-Nordic-5-Clause
 */

#if defined(CONFIG_SOC_NRF54H20)
#include <stdint.h>
#include <stddef.h>

/** @brief Manipulated SUIT envelope, based on ../manifest/sample_valid_54.yaml
 *
 * @details The manipulation is done on byte of index 7, from value 0x58 to 0xFF
 *
 */
const uint8_t manifest_manipulated_buf[] = {
	0xD8, 0x6B, 0xA4, 0x02, 0x58, 0x7A, 0x82, 0x58, 0x24, 0x82, 0x2F, 0xFF, 0x20, 0xAA, 0x37,
	0x14, 0x02, 0x4B, 0x61, 0x72, 0xB5, 0xF6, 0x37, 0xB4, 0xF5, 0x1B, 0xC2, 0xE4, 0x3D, 0x09,
	0x0C, 0xE2, 0xC5, 0xC6, 0x88, 0xF1, 0x36, 0x81, 0x2A, 0xD7, 0xD3, 0x75, 0x4C, 0x87, 0x54,
	0x58, 0x51, 0xD2, 0x84, 0x4A, 0xA2, 0x01, 0x26, 0x04, 0x45, 0x1A, 0x7F, 0xFF, 0xFF, 0xE0,
	0xA0, 0xF6, 0x58, 0x40, 0x00, 0xBE, 0x05, 0x80, 0x8B, 0x64, 0xFD, 0xAF, 0xE7, 0xA1, 0x05,
	0x6B, 0xAE, 0x27, 0x94, 0x08, 0x97, 0xD7, 0x1F, 0xB8, 0x94, 0x28, 0xF4, 0x7C, 0x73, 0x25,
	0x43, 0x7C, 0x53, 0x8D, 0xC5, 0x6C, 0x96, 0x89, 0x31, 0x92, 0x80, 0x3A, 0x00, 0x1B, 0x0A,
	0x21, 0x0C, 0x90, 0x5C, 0x12, 0xD0, 0xB9, 0xFE, 0xF4, 0xD1, 0x3E, 0xB7, 0x1F, 0xDA, 0xED,
	0x3C, 0x58, 0x5A, 0x3A, 0x60, 0x61, 0xFA, 0x66, 0x03, 0x59, 0x01, 0x07, 0xA8, 0x01, 0x01,
	0x02, 0x01, 0x03, 0x58, 0x66, 0xA3, 0x02, 0x82, 0x82, 0x4A, 0x69, 0x43, 0x41, 0x4E, 0x44,
	0x5F, 0x4D, 0x46, 0x53, 0x54, 0x41, 0x00, 0x82, 0x4C, 0x6B, 0x49, 0x4E, 0x53, 0x54, 0x4C,
	0x44, 0x5F, 0x4D, 0x46, 0x53, 0x54, 0x50, 0x5B, 0x46, 0x9F, 0xD1, 0x90, 0xEE, 0x53, 0x9C,
	0xA3, 0x18, 0x68, 0x1B, 0x03, 0x69, 0x5E, 0x36, 0x04, 0x58, 0x2D, 0x88, 0x0C, 0x01, 0x14,
	0xA2, 0x01, 0x50, 0x76, 0x17, 0xDA, 0xA5, 0x71, 0xFD, 0x5A, 0x85, 0x8F, 0x94, 0xE2, 0x8D,
	0x73, 0x5C, 0xE9, 0xF4, 0x02, 0x50, 0x5B, 0x46, 0x9F, 0xD1, 0x90, 0xEE, 0x53, 0x9C, 0xA3,
	0x18, 0x68, 0x1B, 0x03, 0x69, 0x5E, 0x36, 0x01, 0x0F, 0x02, 0x0F, 0x01, 0xA2, 0x00, 0xA0,
	0x01, 0xA0, 0x07, 0x47, 0x86, 0x0C, 0x01, 0x07, 0x0F, 0x0B, 0x0F, 0x09, 0x47, 0x86, 0x0C,
	0x01, 0x07, 0x0F, 0x0B, 0x0F, 0x11, 0x58, 0x3F, 0x8C, 0x0C, 0x00, 0x14, 0xA2, 0x15, 0x69,
	0x23, 0x61, 0x70, 0x70, 0x2E, 0x73, 0x75, 0x69, 0x74, 0x03, 0x58, 0x24, 0x82, 0x2F, 0x58,
	0x20, 0x67, 0xBE, 0x1B, 0x3A, 0x2B, 0x20, 0xCC, 0x03, 0x4F, 0xB5, 0xAA, 0x49, 0x82, 0xDF,
	0x34, 0x2F, 0x4F, 0xDD, 0x80, 0x60, 0x71, 0x17, 0x13, 0x87, 0xED, 0x06, 0xA0, 0x4F, 0xD3,
	0x31, 0xC3, 0x61, 0x15, 0x02, 0x03, 0x0F, 0x07, 0x0F, 0x0B, 0x0F, 0x17, 0x82, 0x2F, 0x58,
	0x20, 0x4C, 0x3E, 0x23, 0xA0, 0xD3, 0x56, 0xE9, 0xA6, 0xF7, 0xDA, 0xD8, 0x0C, 0xAB, 0x79,
	0x53, 0x8F, 0x88, 0xCD, 0x18, 0xC7, 0x17, 0x35, 0xDE, 0xCB, 0x4A, 0xF5, 0x3C, 0xC2, 0xE8,
	0xD6, 0x26, 0xC9, 0x05, 0x82, 0x4C, 0x6B, 0x49, 0x4E, 0x53, 0x54, 0x4C, 0x44, 0x5F, 0x4D,
	0x46, 0x53, 0x54, 0x50, 0x97, 0x05, 0x48, 0x23, 0x4C, 0x3D, 0x59, 0xA1, 0x89, 0x86, 0xA5,
	0x46, 0x60, 0xA1, 0x4B, 0x0A, 0x17, 0x58, 0x77, 0xA1, 0x82, 0x4A, 0x69, 0x43, 0x41, 0x4E,
	0x44, 0x5F, 0x4D, 0x46, 0x53, 0x54, 0x41, 0x00, 0xA6, 0x01, 0x78, 0x18, 0x4E, 0x6F, 0x72,
	0x64, 0x69, 0x63, 0x20, 0x53, 0x65, 0x6D, 0x69, 0x63, 0x6F, 0x6E, 0x64, 0x75, 0x63, 0x74,
	0x6F, 0x72, 0x20, 0x41, 0x53, 0x41, 0x02, 0x64, 0x74, 0x65, 0x73, 0x74, 0x03, 0x6E, 0x6E,
	0x6F, 0x72, 0x64, 0x69, 0x63, 0x73, 0x65, 0x6D, 0x69, 0x2E, 0x63, 0x6F, 0x6D, 0x04, 0x76,
	0x54, 0x68, 0x65, 0x20, 0x74, 0x65, 0x73, 0x74, 0x20, 0x72, 0x6F, 0x6F, 0x74, 0x20, 0x6D,
	0x61, 0x6E, 0x69, 0x66, 0x65, 0x73, 0x74, 0x05, 0x74, 0x53, 0x61, 0x6D, 0x70, 0x6C, 0x65,
	0x20, 0x72, 0x6F, 0x6F, 0x74, 0x20, 0x6D, 0x61, 0x6E, 0x69, 0x66, 0x65, 0x73, 0x74, 0x06,
	0x66, 0x76, 0x31, 0x2E, 0x30, 0x2E, 0x30, 0x69, 0x23, 0x61, 0x70, 0x70, 0x2E, 0x73, 0x75,
	0x69, 0x74, 0x59, 0x02, 0xEE, 0xD8, 0x6B, 0xA4, 0x02, 0x58, 0x7A, 0x82, 0xFF, 0x24, 0x82,
	0x2F, 0x58, 0x20, 0x67, 0xBE, 0x1B, 0x3A, 0x2B, 0x20, 0xCC, 0x03, 0x4F, 0xB5, 0xAA, 0x49,
	0x82, 0xDF, 0x34, 0x2F, 0x4F, 0xDD, 0x80, 0x60, 0x71, 0x17, 0x13, 0x87, 0xED, 0x06, 0xA0,
	0x4F, 0xD3, 0x31, 0xC3, 0x61, 0x58, 0x51, 0xD2, 0x84, 0x4A, 0xA2, 0x01, 0x26, 0x04, 0x45,
	0x1A, 0x7F, 0xFF, 0xFF, 0xE0, 0xA0, 0xF6, 0x58, 0x40, 0xF3, 0x63, 0xA1, 0xC1, 0x0B, 0xB7,
	0x19, 0x0F, 0x26, 0x5C, 0x03, 0x71, 0xFE, 0x2B, 0x1D, 0xE6, 0x56, 0x16, 0xAD, 0x30, 0x40,
	0xE1, 0x97, 0x5B, 0xC9, 0xBB, 0xB3, 0x3A, 0x54, 0xE4, 0x39, 0x9A, 0x29, 0xDE, 0xD7, 0x70,
	0x65, 0x93, 0x83, 0xAD, 0x89, 0xF7, 0x2D, 0x05, 0xE3, 0xEB, 0x54, 0x4B, 0x9B, 0x93, 0x7E,
	0xE4, 0x54, 0x38, 0x8D, 0xBF, 0xBF, 0x2D, 0x1B, 0x7F, 0xAE, 0x8C, 0xD9, 0x4F, 0x03, 0x58,
	0xD9, 0xA8, 0x01, 0x01, 0x02, 0x01, 0x03, 0x58, 0x6E, 0xA2, 0x02, 0x81, 0x84, 0x44, 0x63,
	0x4D, 0x45, 0x4D, 0x41, 0x00, 0x45, 0x1A, 0x0E, 0x0A, 0xA0, 0x00, 0x43, 0x19, 0x10, 0x00,
	0x04, 0x58, 0x56, 0x86, 0x14, 0xA4, 0x01, 0x50, 0x76, 0x17, 0xDA, 0xA5, 0x71, 0xFD, 0x5A,
	0x85, 0x8F, 0x94, 0xE2, 0x8D, 0x73, 0x5C, 0xE9, 0xF4, 0x02, 0x50, 0x5B, 0x46, 0x9F, 0xD1,
	0x90, 0xEE, 0x53, 0x9C, 0xA3, 0x18, 0x68, 0x1B, 0x03, 0x69, 0x5E, 0x36, 0x03, 0x58, 0x24,
	0x82, 0x2F, 0x58, 0x20, 0x5F, 0xC3, 0x54, 0xBF, 0x8E, 0x8C, 0x50, 0xFB, 0x4F, 0xBC, 0x2C,
	0xFA, 0xEB, 0x04, 0x53, 0x41, 0xC9, 0x80, 0x6D, 0xEA, 0xBD, 0xCB, 0x41, 0x54, 0xFB, 0x79,
	0xCC, 0xA4, 0xF0, 0xC9, 0x8C, 0x12, 0x0E, 0x19, 0x01, 0x00, 0x01, 0x0F, 0x02, 0x0F, 0x07,
	0x43, 0x82, 0x03, 0x0F, 0x09, 0x43, 0x82, 0x17, 0x02, 0x11, 0x52, 0x86, 0x14, 0xA1, 0x15,
	0x69, 0x23, 0x66, 0x69, 0x6C, 0x65, 0x2E, 0x62, 0x69, 0x6E, 0x15, 0x02, 0x03, 0x0F, 0x17,
	0x82, 0x2F, 0x58, 0x20, 0x69, 0x74, 0xD1, 0x61, 0x69, 0x08, 0x2F, 0x10, 0xAE, 0x48, 0x6C,
	0x5B, 0x12, 0x82, 0x40, 0x9C, 0xFD, 0x63, 0xCC, 0xC8, 0x35, 0x4D, 0xBE, 0x55, 0x15, 0xCC,
	0xE6, 0xCE, 0x8F, 0x37, 0xDE, 0x71, 0x05, 0x82, 0x4C, 0x6B, 0x49, 0x4E, 0x53, 0x54, 0x4C,
	0x44, 0x5F, 0x4D, 0x46, 0x53, 0x54, 0x50, 0x5B, 0x46, 0x9F, 0xD1, 0x90, 0xEE, 0x53, 0x9C,
	0xA3, 0x18, 0x68, 0x1B, 0x03, 0x69, 0x5E, 0x36, 0x17, 0x58, 0x82, 0xA1, 0x84, 0x44, 0x63,
	0x4D, 0x45, 0x4D, 0x41, 0x00, 0x45, 0x1A, 0x0E, 0x0A, 0xA0, 0x00, 0x43, 0x19, 0x10, 0x00,
	0xA6, 0x01, 0x78, 0x18, 0x4E, 0x6F, 0x72, 0x64, 0x69, 0x63, 0x20, 0x53, 0x65, 0x6D, 0x69,
	0x63, 0x6F, 0x6E, 0x64, 0x75, 0x63, 0x74, 0x6F, 0x72, 0x20, 0x41, 0x53, 0x41, 0x02, 0x64,
	0x74, 0x65, 0x73, 0x74, 0x03, 0x6E, 0x6E, 0x6F, 0x72, 0x64, 0x69, 0x63, 0x73, 0x65, 0x6D,
	0x69, 0x2E, 0x63, 0x6F, 0x6D, 0x04, 0x74, 0x54, 0x68, 0x65, 0x20, 0x74, 0x65, 0x73, 0x74,
	0x20, 0x61, 0x70, 0x70, 0x6C, 0x69, 0x63, 0x61, 0x74, 0x69, 0x6F, 0x6E, 0x05, 0x78, 0x1C,
	0x53, 0x61, 0x6D, 0x70, 0x6C, 0x65, 0x20, 0x61, 0x70, 0x70, 0x6C, 0x69, 0x63, 0x61, 0x74,
	0x69, 0x6F, 0x6E, 0x20, 0x66, 0x6F, 0x72, 0x20, 0x74, 0x65, 0x73, 0x74, 0x73, 0x06, 0x66,
	0x76, 0x31, 0x2E, 0x30, 0x2E, 0x30, 0x69, 0x23, 0x66, 0x69, 0x6C, 0x65, 0x2E, 0x62, 0x69,
	0x6E, 0x59, 0x01, 0x00, 0xC7, 0x9C, 0xAB, 0x9D, 0xE8, 0x33, 0x7F, 0x30, 0x14, 0xEB, 0xAC,
	0x02, 0xAF, 0x26, 0x01, 0x5E, 0x80, 0x6D, 0x88, 0xA1, 0xDB, 0x11, 0xA7, 0x31, 0xDF, 0xA6,
	0xEC, 0xCB, 0x9B, 0x48, 0x0D, 0xC8, 0x34, 0x40, 0x6D, 0x30, 0x86, 0x7D, 0xE8, 0x1B, 0xEC,
	0x3C, 0xF5, 0x40, 0xD0, 0x48, 0x18, 0x82, 0x11, 0x9D, 0x7C, 0x3F, 0x6C, 0xE5, 0x8F, 0xF1,
	0xD3, 0x5D, 0xE1, 0x51, 0xF7, 0x6A, 0x0F, 0xAF, 0x0B, 0xBD, 0x4C, 0x5F, 0xA5, 0x34, 0x1A,
	0x66, 0xDB, 0x22, 0xEC, 0x63, 0xED, 0x4B, 0xAB, 0xC7, 0xC8, 0xF7, 0x59, 0xD8, 0xD6, 0x9E,
	0xEC, 0x71, 0x1B, 0x24, 0x20, 0xB9, 0xAE, 0xE1, 0x3B, 0xFC, 0xAE, 0xB8, 0x77, 0xAC, 0xA4,
	0x57, 0x34, 0x97, 0x84, 0x4F, 0x58, 0xD5, 0x68, 0x08, 0x6F, 0xE3, 0x9C, 0x7E, 0x1B, 0xD7,
	0x38, 0x22, 0x98, 0x48, 0xF8, 0x7A, 0x67, 0xB2, 0xD9, 0xAC, 0xC5, 0x34, 0xC1, 0x27, 0x82,
	0x8E, 0x42, 0x79, 0x84, 0x21, 0x37, 0x4C, 0x41, 0x4A, 0x0F, 0xE2, 0x7F, 0xA0, 0x6A, 0x19,
	0x13, 0x3D, 0x52, 0x22, 0x7F, 0xD6, 0x2F, 0x71, 0x12, 0x76, 0xAB, 0x25, 0x9C, 0xFC, 0x67,
	0x08, 0x03, 0x7C, 0xDB, 0x18, 0xE6, 0x45, 0xF8, 0x99, 0xC2, 0x9E, 0x2C, 0xE3, 0x9B, 0x25,
	0xA9, 0x7B, 0x09, 0xFF, 0x00, 0x57, 0x26, 0x08, 0x0A, 0x11, 0x42, 0xCF, 0x82, 0xA2, 0x6B,
	0x2A, 0x99, 0xF9, 0x71, 0x9D, 0x14, 0x19, 0x5C, 0x5C, 0x78, 0x31, 0x60, 0x42, 0x4A, 0x18,
	0x1F, 0xEC, 0x78, 0x6A, 0x9A, 0x7C, 0x4F, 0xCF, 0xE8, 0x5A, 0x29, 0x65, 0xCD, 0x01, 0x3B,
	0x6D, 0x53, 0xBB, 0xC6, 0xDB, 0xDA, 0xD5, 0x8F, 0xF7, 0xF4, 0xD9, 0xB9, 0x0A, 0x03, 0x4B,
	0xFF, 0x33, 0xAB, 0x3B, 0xC5, 0xAF, 0xD0, 0xB8, 0x2C, 0x0F, 0x6A, 0xA9, 0x11, 0xB0, 0xE8,
	0x57, 0x8C, 0x92, 0x53, 0x81};

const size_t manifest_manipulated_len = sizeof(manifest_manipulated_buf);

#endif /* CONFIG_SOC_NRF54H20 */
```

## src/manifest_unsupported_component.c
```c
/*
 * Copyright (c) 2023 Nordic Semiconductor ASA
 *
 * SPDX-License-Identifier: LicenseRef-Nordic-5-Clause
 */

#if defined(CONFIG_SOC_NRF52840) || defined(CONFIG_BOARD_NATIVE_POSIX)
#include <stdint.h>
#include <stddef.h>

/** @brief Invalid SUIT envelope, based on ../manifest/sample_unsupported_component.yaml
 *
 * @note Component type is set to "X"
 */
const uint8_t manifest_unsupported_component_buf[] = {
	0xD8, 0x6B, 0xA4, 0x02, 0x58, 0x7A, 0x82, 0x58, 0x24, 0x82, 0x2F, 0x58, 0x20, 0x0E, 0x56,
	0x54, 0x22, 0x18, 0xFF, 0x65, 0x7E, 0x56, 0x2C, 0x67, 0x89, 0x1C, 0x1E, 0x07, 0x50, 0xBB,
	0x40, 0x4F, 0x11, 0xFE, 0xCE, 0xE6, 0xEA, 0x87, 0x67, 0xE3, 0x7F, 0x6D, 0x64, 0xED, 0x61,
	0x58, 0x51, 0xD2, 0x84, 0x4A, 0xA2, 0x01, 0x26, 0x04, 0x45, 0x1A, 0x7F, 0xFF, 0xFF, 0xE0,
	0xA0, 0xF6, 0x58, 0x40, 0xBD, 0xBD, 0x52, 0x90, 0x57, 0x0A, 0xF0, 0x3F, 0xAF, 0x48, 0x69,
	0xF0, 0xC9, 0xA1, 0x82, 0x6D, 0x7D, 0xBF, 0xFE, 0x1D, 0x72, 0x1E, 0x60, 0x72, 0x0B, 0xA7,
	0x90, 0xEE, 0xD8, 0x48, 0x6F, 0xF7, 0x4A, 0x61, 0x6B, 0xC0, 0x04, 0x27, 0xFA, 0xE5, 0x6D,
	0x91, 0x50, 0x70, 0xD4, 0xD2, 0xFF, 0xA4, 0xC4, 0x63, 0x81, 0x63, 0x5B, 0x1F, 0x4B, 0x1C,
	0xD8, 0x50, 0x1F, 0x0C, 0x9A, 0x98, 0xC8, 0xE8, 0x03, 0x58, 0xC7, 0xA8, 0x01, 0x01, 0x02,
	0x01, 0x03, 0x58, 0x67, 0xA2, 0x02, 0x81, 0x84, 0x41, 0x58, 0x41, 0x02, 0x45, 0x1A, 0x00,
	0x08, 0x00, 0x00, 0x43, 0x19, 0x01, 0x00, 0x04, 0x58, 0x52, 0x86, 0x14, 0xA3, 0x01, 0x50,
	0x76, 0x17, 0xDA, 0xA5, 0x71, 0xFD, 0x5A, 0x85, 0x8F, 0x94, 0xE2, 0x8D, 0x73, 0x5C, 0xE9,
	0xF4, 0x02, 0x50, 0x5B, 0x46, 0x9F, 0xD1, 0x90, 0xEE, 0x53, 0x9C, 0xA3, 0x18, 0x68, 0x1B,
	0x03, 0x69, 0x5E, 0x36, 0x03, 0x58, 0x24, 0x82, 0x2F, 0x58, 0x20, 0x5F, 0xC3, 0x54, 0xBF,
	0x8E, 0x8C, 0x50, 0xFB, 0x4F, 0xBC, 0x2C, 0xFA, 0xEB, 0x04, 0x53, 0x41, 0xC9, 0x80, 0x6D,
	0xEA, 0xBD, 0xCB, 0x41, 0x54, 0xFB, 0x79, 0xCC, 0xA4, 0xF0, 0xC9, 0x8C, 0x12, 0x01, 0x0F,
	0x02, 0x0F, 0x07, 0x43, 0x82, 0x03, 0x0F, 0x09, 0x43, 0x82, 0x17, 0x02, 0x11, 0x52, 0x86,
	0x14, 0xA1, 0x15, 0x69, 0x23, 0x66, 0x69, 0x6C, 0x65, 0x2E, 0x62, 0x69, 0x6E, 0x15, 0x02,
	0x03, 0x0F, 0x17, 0x82, 0x2F, 0x58, 0x20, 0x32, 0xB1, 0xBE, 0x58, 0x02, 0x2A, 0x89, 0x6C,
	0x3F, 0x42, 0x5D, 0x96, 0x1B, 0x4B, 0x1B, 0xE0, 0xDD, 0x4B, 0x50, 0x0E, 0x24, 0xFA, 0x1A,
	0x09, 0x77, 0xA2, 0xF6, 0x07, 0xB1, 0x73, 0x5B, 0xF0, 0x05, 0x82, 0x41, 0x49, 0x50, 0x5B,
	0x46, 0x9F, 0xD1, 0x90, 0xEE, 0x53, 0x9C, 0xA3, 0x18, 0x68, 0x1B, 0x03, 0x69, 0x5E, 0x36,
	0x17, 0x58, 0x7F, 0xA1, 0x84, 0x41, 0x58, 0x41, 0x02, 0x45, 0x1A, 0x00, 0x08, 0x00, 0x00,
	0x43, 0x19, 0x01, 0x00, 0xA6, 0x01, 0x78, 0x18, 0x4E, 0x6F, 0x72, 0x64, 0x69, 0x63, 0x20,
	0x53, 0x65, 0x6D, 0x69, 0x63, 0x6F, 0x6E, 0x64, 0x75, 0x63, 0x74, 0x6F, 0x72, 0x20, 0x41,
	0x53, 0x41, 0x02, 0x64, 0x74, 0x65, 0x73, 0x74, 0x03, 0x6E, 0x6E, 0x6F, 0x72, 0x64, 0x69,
	0x63, 0x73, 0x65, 0x6D, 0x69, 0x2E, 0x63, 0x6F, 0x6D, 0x04, 0x74, 0x54, 0x68, 0x65, 0x20,
	0x74, 0x65, 0x73, 0x74, 0x20, 0x61, 0x70, 0x70, 0x6C, 0x69, 0x63, 0x61, 0x74, 0x69, 0x6F,
	0x6E, 0x05, 0x78, 0x1C, 0x53, 0x61, 0x6D, 0x70, 0x6C, 0x65, 0x20, 0x61, 0x70, 0x70, 0x6C,
	0x69, 0x63, 0x61, 0x74, 0x69, 0x6F, 0x6E, 0x20, 0x66, 0x6F, 0x72, 0x20, 0x74, 0x65, 0x73,
	0x74, 0x73, 0x06, 0x66, 0x76, 0x31, 0x2E, 0x30, 0x2E, 0x30, 0x69, 0x23, 0x66, 0x69, 0x6C,
	0x65, 0x2E, 0x62, 0x69, 0x6E, 0x59, 0x01, 0x00, 0xC7, 0x9C, 0xAB, 0x9D, 0xE8, 0x33, 0x7F,
	0x30, 0x14, 0xEB, 0xAC, 0x02, 0xAF, 0x26, 0x01, 0x5E, 0x80, 0x6D, 0x88, 0xA1, 0xDB, 0x11,
	0xA7, 0x31, 0xDF, 0xA6, 0xEC, 0xCB, 0x9B, 0x48, 0x0D, 0xC8, 0x34, 0x40, 0x6D, 0x30, 0x86,
	0x7D, 0xE8, 0x1B, 0xEC, 0x3C, 0xF5, 0x40, 0xD0, 0x48, 0x18, 0x82, 0x11, 0x9D, 0x7C, 0x3F,
	0x6C, 0xE5, 0x8F, 0xF1, 0xD3, 0x5D, 0xE1, 0x51, 0xF7, 0x6A, 0x0F, 0xAF, 0x0B, 0xBD, 0x4C,
	0x5F, 0xA5, 0x34, 0x1A, 0x66, 0xDB, 0x22, 0xEC, 0x63, 0xED, 0x4B, 0xAB, 0xC7, 0xC8, 0xF7,
	0x59, 0xD8, 0xD6, 0x9E, 0xEC, 0x71, 0x1B, 0x24, 0x20, 0xB9, 0xAE, 0xE1, 0x3B, 0xFC, 0xAE,
	0xB8, 0x77, 0xAC, 0xA4, 0x57, 0x34, 0x97, 0x84, 0x4F, 0x58, 0xD5, 0x68, 0x08, 0x6F, 0xE3,
	0x9C, 0x7E, 0x1B, 0xD7, 0x38, 0x22, 0x98, 0x48, 0xF8, 0x7A, 0x67, 0xB2, 0xD9, 0xAC, 0xC5,
	0x34, 0xC1, 0x27, 0x82, 0x8E, 0x42, 0x79, 0x84, 0x21, 0x37, 0x4C, 0x41, 0x4A, 0x0F, 0xE2,
	0x7F, 0xA0, 0x6A, 0x19, 0x13, 0x3D, 0x52, 0x22, 0x7F, 0xD6, 0x2F, 0x71, 0x12, 0x76, 0xAB,
	0x25, 0x9C, 0xFC, 0x67, 0x08, 0x03, 0x7C, 0xDB, 0x18, 0xE6, 0x45, 0xF8, 0x99, 0xC2, 0x9E,
	0x2C, 0xE3, 0x9B, 0x25, 0xA9, 0x7B, 0x09, 0xFF, 0x00, 0x57, 0x26, 0x08, 0x0A, 0x11, 0x42,
	0xCF, 0x82, 0xA2, 0x6B, 0x2A, 0x99, 0xF9, 0x71, 0x9D, 0x14, 0x19, 0x5C, 0x5C, 0x78, 0x31,
	0x60, 0x42, 0x4A, 0x18, 0x1F, 0xEC, 0x78, 0x6A, 0x9A, 0x7C, 0x4F, 0xCF, 0xE8, 0x5A, 0x29,
	0x65, 0xCD, 0x01, 0x3B, 0x6D, 0x53, 0xBB, 0xC6, 0xDB, 0xDA, 0xD5, 0x8F, 0xF7, 0xF4, 0xD9,
	0xB9, 0x0A, 0x03, 0x4B, 0xFF, 0x33, 0xAB, 0x3B, 0xC5, 0xAF, 0xD0, 0xB8, 0x2C, 0x0F, 0x6A,
	0xA9, 0x11, 0xB0, 0xE8, 0x57, 0x8C, 0x92, 0x53, 0x81};

const size_t manifest_unsupported_component_len = sizeof(manifest_unsupported_component_buf);

#endif /* CONFIG_SOC_NRF52840 || CONFIG_BOARD_NATIVE_POSIX */
```
